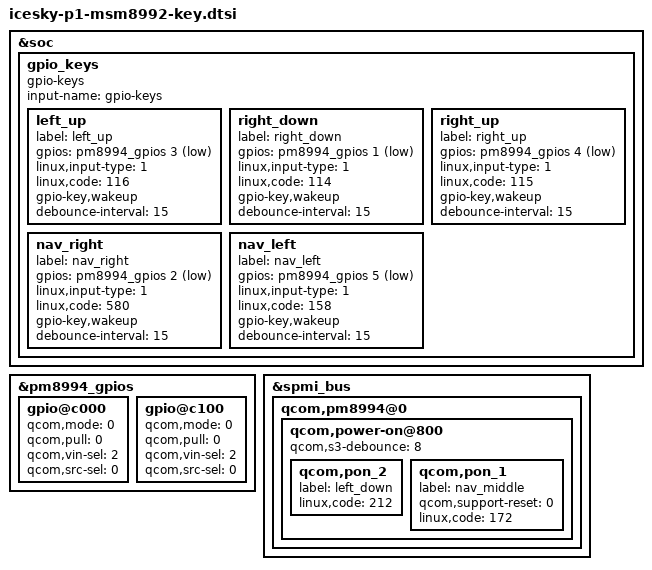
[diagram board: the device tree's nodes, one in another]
/* Copyright (c) 2014, The Linux Foundation. All rights reserved.
 *
 * This program is free software; you can redistribute it and/or modify
 * it under the terms of the GNU General Public License version 2 and
 * only version 2 as published by the Free Software Foundation.
 *
 * This program is distributed in the hope that it will be useful,
 * but WITHOUT ANY WARRANTY; without even the implied warranty of
 * MERCHANTABILITY or FITNESS FOR A PARTICULAR PURPOSE.  See the
 * GNU General Public License for more details.
 */

/* Overlay the msm8994-mtp.dtsi */
&soc {
	gpio_keys {
		compatible = "gpio-keys";
		input-name = "gpio-keys";

		/* Left up */
		left_up {
			label = "left_up";
			gpios = <&pm8994_gpios 3 0x1>;
			linux,input-type = <1>;
			linux,code = <116>;
			gpio-key,wakeup;
			debounce-interval = <15>;
		};

		/* Right down */
		right_down {
			label = "right_down";
			gpios = <&pm8994_gpios 1 0x1>;
			linux,input-type = <1>;
			linux,code = <114>;
			gpio-key,wakeup;
			debounce-interval = <15>;
		};

		/* Right up */
		right_up {
			label = "right_up";
			gpios = <&pm8994_gpios 4 0x1>;
			linux,input-type = <1>;
			linux,code = <115>;
			gpio-key,wakeup;
			debounce-interval = <15>;
		};

		/* Nav right */
		nav_right {
			label = "nav_right";
			gpios = <&pm8994_gpios 2 0x1>;
			linux,input-type = <1>;
			linux,code = <580>;
			gpio-key,wakeup;
			debounce-interval = <15>;
		};

		/* Nav left */
		nav_left {
			label = "nav_left";
			gpios = <&pm8994_gpios 5 0x1>;
			linux,input-type = <1>;
			linux,code = <158>;
			gpio-key,wakeup;
			debounce-interval = <15>;
		};
	};
};

&pm8994_gpios {
	gpio@c000 { /* GPIO 1 */
		qcom,mode = <0>;
		qcom,pull = <0>;
		qcom,vin-sel = <2>;
		qcom,src-sel = <0>;
		status = "okay";
	};

	gpio@c100 { /* GPIO 2 */
		qcom,mode = <0>;
		qcom,pull = <0>;
		qcom,vin-sel = <2>;
		qcom,src-sel = <0>;
		status = "okay";
	};
};

/* Overlay the msm8994-mtp.dtsi */
&spmi_bus {
	qcom,pm8994@0 {
		qcom,power-on@800 {
			qcom,s3-debounce = <8>;

			/* Left down */
			qcom,pon_2 {
				label = "left_down";
				linux,code = <212>;
			};

			/* Nav middle */
			qcom,pon_1 {
				label = "nav_middle";
				qcom,support-reset = <0>;
				linux,code = <172>;
			};
		};
	};
};
